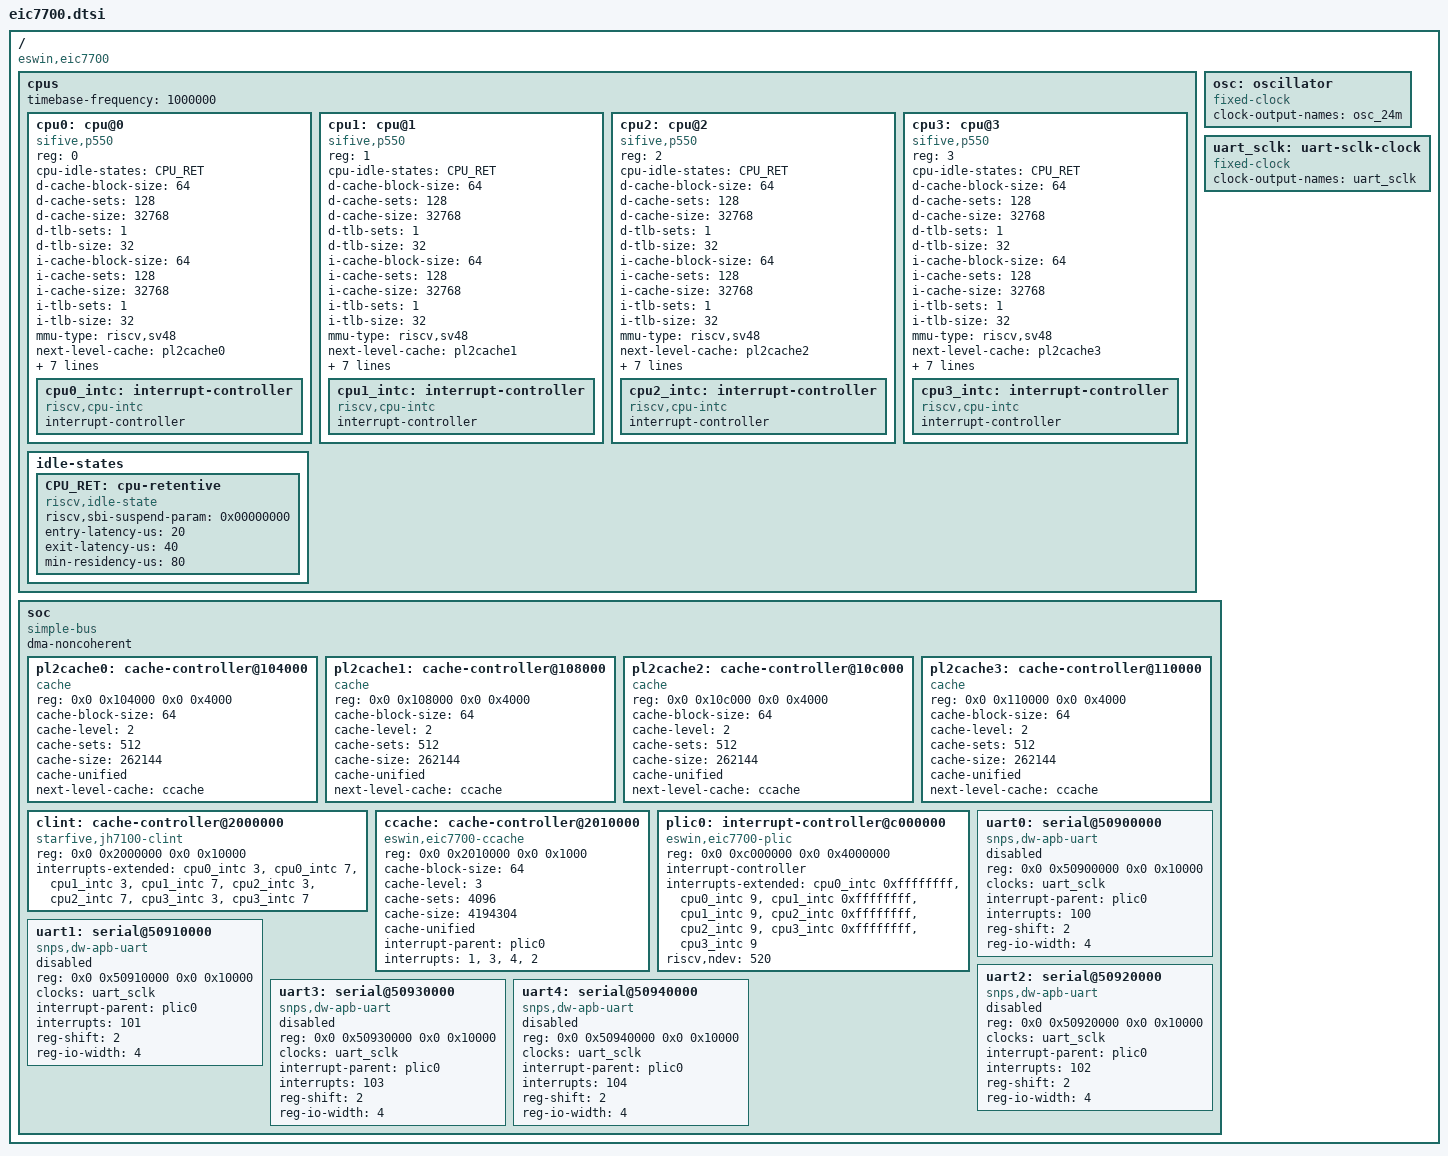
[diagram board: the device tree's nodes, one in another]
// SPDX-License-Identifier: (GPL-2.0 OR MIT)
/*
 * Copyright (C) 2024 Inochi Amaoto <inochiama@outlook.com>
 */

#include <dt-bindings/interrupt-controller/irq.h>

/ {
	compatible = "eswin,eic7700";
	#address-cells = <2>;
	#size-cells = <2>;

	cpus: cpus {
		#address-cells = <1>;
		#size-cells = <0>;
		timebase-frequency = <1000000>;

		cpu0: cpu@0 {
			compatible = "sifive,p550", "riscv";
			device_type = "cpu";
			reg = <0>;
			#cooling-cells = <2>;
			cpu-idle-states = <&CPU_RET>;
			d-cache-block-size = <64>;
			d-cache-sets = <128>;
			d-cache-size = <32768>;
			d-tlb-sets = <1>;
			d-tlb-size = <32>;
			i-cache-block-size = <64>;
			i-cache-sets = <128>;
			i-cache-size = <32768>;
			i-tlb-sets = <1>;
			i-tlb-size = <32>;
			mmu-type = "riscv,sv48";
			next-level-cache = <&pl2cache0>;
			numa-node-id = <0>;
			tlb-split;
			riscv,isa = "rv64imafdc";
			riscv,isa-base = "rv64i";
			riscv,isa-extensions = "i", "m", "a", "f", "d", "c",
					       "sscofpmf", "zba", "zbb",
					       "zicntr", "zicsr", "zifencei",
					       "zihpm";

			cpu0_intc: interrupt-controller {
				compatible = "riscv,cpu-intc";
				interrupt-controller;
				#interrupt-cells = <1>;
			};
		};

		cpu1: cpu@1 {
			compatible = "sifive,p550", "riscv";
			device_type = "cpu";
			reg = <1>;
			#cooling-cells = <2>;
			cpu-idle-states = <&CPU_RET>;
			d-cache-block-size = <64>;
			d-cache-sets = <128>;
			d-cache-size = <32768>;
			d-tlb-sets = <1>;
			d-tlb-size = <32>;
			i-cache-block-size = <64>;
			i-cache-sets = <128>;
			i-cache-size = <32768>;
			i-tlb-sets = <1>;
			i-tlb-size = <32>;
			mmu-type = "riscv,sv48";
			next-level-cache = <&pl2cache1>;
			numa-node-id = <0>;
			tlb-split;
			riscv,isa = "rv64imafdc";
			riscv,isa-base = "rv64i";
			riscv,isa-extensions = "i", "m", "a", "f", "d", "c",
					       "sscofpmf", "zba", "zbb",
					       "zicntr", "zicsr", "zifencei",
					       "zihpm";

			cpu1_intc: interrupt-controller {
				compatible = "riscv,cpu-intc";
				interrupt-controller;
				#interrupt-cells = <1>;
			};
		};

		cpu2: cpu@2 {
			compatible = "sifive,p550", "riscv";
			device_type = "cpu";
			reg = <2>;
			#cooling-cells = <2>;
			cpu-idle-states = <&CPU_RET>;
			d-cache-block-size = <64>;
			d-cache-sets = <128>;
			d-cache-size = <32768>;
			d-tlb-sets = <1>;
			d-tlb-size = <32>;
			i-cache-block-size = <64>;
			i-cache-sets = <128>;
			i-cache-size = <32768>;
			i-tlb-sets = <1>;
			i-tlb-size = <32>;
			mmu-type = "riscv,sv48";
			next-level-cache = <&pl2cache2>;
			numa-node-id = <0>;
			tlb-split;
			riscv,isa = "rv64imafdc";
			riscv,isa-base = "rv64i";
			riscv,isa-extensions = "i", "m", "a", "f", "d", "c",
					       "sscofpmf", "zba", "zbb",
					       "zicntr", "zicsr", "zifencei",
					       "zihpm";

			cpu2_intc: interrupt-controller {
				compatible = "riscv,cpu-intc";
				interrupt-controller;
				#interrupt-cells = <1>;
			};
		};

		cpu3: cpu@3 {
			compatible = "sifive,p550", "riscv";
			device_type = "cpu";
			reg = <3>;
			#cooling-cells = <2>;
			cpu-idle-states = <&CPU_RET>;
			d-cache-block-size = <64>;
			d-cache-sets = <128>;
			d-cache-size = <32768>;
			d-tlb-sets = <1>;
			d-tlb-size = <32>;
			i-cache-block-size = <64>;
			i-cache-sets = <128>;
			i-cache-size = <32768>;
			i-tlb-sets = <1>;
			i-tlb-size = <32>;
			mmu-type = "riscv,sv48";
			next-level-cache = <&pl2cache3>;
			numa-node-id = <0>;
			tlb-split;
			riscv,isa = "rv64imafdc";
			riscv,isa-base = "rv64i";
			riscv,isa-extensions = "i", "m", "a", "f", "d", "c",
					       "sscofpmf", "zba", "zbb",
					       "zicntr", "zicsr", "zifencei",
					       "zihpm";

			cpu3_intc: interrupt-controller {
				compatible = "riscv,cpu-intc";
				interrupt-controller;
				#interrupt-cells = <1>;
			};
		};

		idle-states {
			CPU_RET: cpu-retentive {
				compatible = "riscv,idle-state";
				riscv,sbi-suspend-param = <0x00000000>;
				entry-latency-us = <20>;
				exit-latency-us = <40>;
				min-residency-us = <80>;
			};
		};

	};

	osc: oscillator {
		compatible = "fixed-clock";
		clock-output-names = "osc_24m";
		#clock-cells = <0>;
	};

	uart_sclk: uart-sclk-clock {
		compatible = "fixed-clock";
		clock-output-names = "uart_sclk";
		#clock-cells = <0>;
	};

	soc {
		compatible = "simple-bus";
		#address-cells = <2>;
		#size-cells = <2>;
		dma-noncoherent;
		ranges;

		pl2cache0: cache-controller@104000 {
			compatible = "cache";
			reg = <0x0 0x104000 0x0 0x4000>;
			cache-block-size = <64>;
			cache-level = <2>;
			cache-sets = <512>;
			cache-size = <262144>;
			cache-unified;
			next-level-cache = <&ccache>;
		};

		pl2cache1: cache-controller@108000 {
			compatible = "cache";
			reg = <0x0 0x108000 0x0 0x4000>;
			cache-block-size = <64>;
			cache-level = <2>;
			cache-sets = <512>;
			cache-size = <262144>;
			cache-unified;
			next-level-cache = <&ccache>;
		};

		pl2cache2: cache-controller@10c000 {
			compatible = "cache";
			reg = <0x0 0x10c000 0x0 0x4000>;
			cache-block-size = <64>;
			cache-level = <2>;
			cache-sets = <512>;
			cache-size = <262144>;
			cache-unified;
			next-level-cache = <&ccache>;
		};

		pl2cache3: cache-controller@110000 {
			compatible = "cache";
			reg = <0x0 0x110000 0x0 0x4000>;
			cache-block-size = <64>;
			cache-level = <2>;
			cache-sets = <512>;
			cache-size = <262144>;
			cache-unified;
			next-level-cache = <&ccache>;
		};

		clint: cache-controller@2000000 {
			compatible = "starfive,jh7100-clint", "sifive,clint0";
			reg = <0x0 0x2000000 0x0 0x10000>;
			interrupts-extended = <&cpu0_intc 3>, <&cpu0_intc 7>,
					      <&cpu1_intc 3>, <&cpu1_intc 7>,
					      <&cpu2_intc 3>, <&cpu2_intc 7>,
					      <&cpu3_intc 3>, <&cpu3_intc 7>;
		};

		ccache: cache-controller@2010000 {
			compatible = "eswin,eic7700-ccache", "sifive,ccache0", "cache";
			reg = <0x0 0x2010000 0x0 0x1000>;
			cache-block-size = <64>;
			cache-level = <3>;
			cache-sets = <4096>;
			cache-size = <4194304>;
			cache-unified;
			interrupt-parent = <&plic0>;
			interrupts = <1>, <3>, <4>, <2>;
		};

		plic0: interrupt-controller@c000000 {
			compatible = "eswin,eic7700-plic","sifive,plic-1.0.0";
			reg = <0x0 0xc000000 0x0 0x4000000>;
			#interrupt-cells = <1>;
			#address-cells = <0>;
			interrupt-controller;
			interrupts-extended =
				<&cpu0_intc 0xffffffff &cpu0_intc 9>,
				<&cpu1_intc 0xffffffff &cpu1_intc 9>,
				<&cpu2_intc 0xffffffff &cpu2_intc 9>,
				<&cpu3_intc 0xffffffff &cpu3_intc 9>;
			riscv,ndev = <520>;
		};

		uart0: serial@50900000 {
			compatible = "snps,dw-apb-uart";
			reg = <0x0 0x50900000 0x0 0x10000>;
			clocks = <&uart_sclk>;
			interrupt-parent = <&plic0>;
			interrupts = <100>;
			reg-shift = <2>;
			reg-io-width = <4>;
			status = "disabled";
		};

		uart1: serial@50910000 {
			compatible = "snps,dw-apb-uart";
			reg = <0x0 0x50910000 0x0 0x10000>;
			clocks = <&uart_sclk>;
			interrupt-parent = <&plic0>;
			interrupts = <101>;
			reg-shift = <2>;
			reg-io-width = <4>;
			status = "disabled";
		};

		uart2: serial@50920000 {
			compatible = "snps,dw-apb-uart";
			reg = <0x0 0x50920000 0x0 0x10000>;
			clocks = <&uart_sclk>;
			interrupt-parent = <&plic0>;
			interrupts = <102>;
			reg-shift = <2>;
			reg-io-width = <4>;
			status = "disabled";
		};

		uart3: serial@50930000 {
			compatible = "snps,dw-apb-uart";
			reg = <0x0 0x50930000 0x0 0x10000>;
			clocks = <&uart_sclk>;
			interrupt-parent = <&plic0>;
			interrupts = <103>;
			reg-shift = <2>;
			reg-io-width = <4>;
			status = "disabled";
		};

		uart4: serial@50940000 {
			compatible = "snps,dw-apb-uart";
			reg = <0x0 0x50940000 0x0 0x10000>;
			clocks = <&uart_sclk>;
			interrupt-parent = <&plic0>;
			interrupts = <104>;
			reg-shift = <2>;
			reg-io-width = <4>;
			status = "disabled";
		};
	};
};
